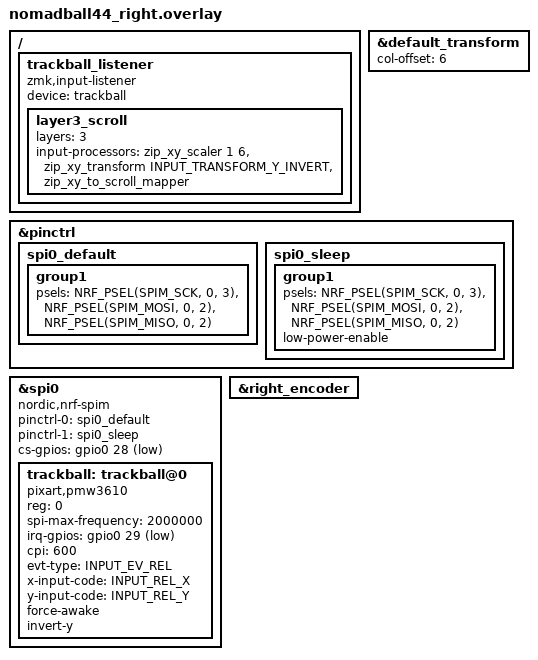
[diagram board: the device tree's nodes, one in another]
// This file was generated from a template. Edit it to match your keyboard.
// See https://zmk.dev/docs/development/hardware-integration/new-shield for more
// instructions.

#include "nomadball44.dtsi"
#include <zephyr/dt-bindings/input/input-event-codes.h>
#include <dt-bindings/zmk/input_transform.h>
#include <input/processors.dtsi>

&default_transform {
    // Set this to the number of columns on the left side.
    col-offset = <6>;
};

&pinctrl {
    spi0_default: spi0_default {
        group1 {
            /* NomadBall44: D0=SDIO, D1=SCLK (半二重: MOSI/MISO同一ピン) */
            psels = <NRF_PSEL(SPIM_SCK, 0, 3)>,
                    <NRF_PSEL(SPIM_MOSI, 0, 2)>,
                    <NRF_PSEL(SPIM_MISO, 0, 2)>;
        };
    };
    spi0_sleep: spi0_sleep {
        group1 {
            psels = <NRF_PSEL(SPIM_SCK, 0, 3)>,
                    <NRF_PSEL(SPIM_MOSI, 0, 2)>,
                    <NRF_PSEL(SPIM_MISO, 0, 2)>;
            low-power-enable;
        };
    };
};

&spi0 {
    status = "okay";
    compatible = "nordic,nrf-spim";
    pinctrl-0 = <&spi0_default>;
    pinctrl-1 = <&spi0_sleep>;
    pinctrl-names = "default", "sleep";
    cs-gpios = <&gpio0 28 GPIO_ACTIVE_LOW>;  /* D2 = P0.28 (nCS) */

    trackball: trackball@0 {
        status = "okay";
        compatible = "pixart,pmw3610";
        reg = <0>;
        spi-max-frequency = <2000000>;
        irq-gpios = <&gpio0 29 (GPIO_ACTIVE_LOW | GPIO_PULL_UP)>;  /* D3 = P0.29 (MOTION) */
        cpi = <600>;
        evt-type = <INPUT_EV_REL>;
        x-input-code = <INPUT_REL_X>;
        y-input-code = <INPUT_REL_Y>;
        force-awake;
        /* force-awake-4ms-mode; */  /* USB接続で250Hzが必要な場合 */
        // swap-xy;   /* センサー向きに応じて */
        // invert-x;
        invert-y;
    };
};

/ {
    trackball_listener {
        compatible = "zmk,input-listener";
        device = <&trackball>;

        layer3_scroll {
            layers = <3>;
            /* 縦スクロール向きのみ反転（横はそのまま） */
            input-processors =
                <&zip_xy_scaler 1 6
                 &zip_xy_transform INPUT_TRANSFORM_Y_INVERT
                 &zip_xy_to_scroll_mapper>;
        };
    };
};

&right_encoder {
    status = "okay";
};
